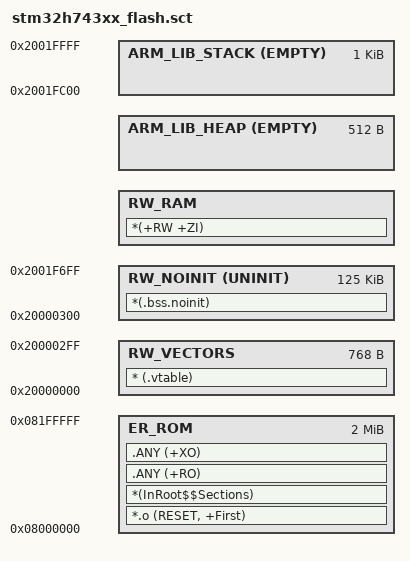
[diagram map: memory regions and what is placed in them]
#! armclang -E --target=arm-arm-none-eabi -mcpu=cortex-m7 -xc
; command above MUST be in first line (no comment above!)

/*
;-------- <<< Use Configuration Wizard in Context Menu >>> -------------------
*/

/*--------------------- Flash Configuration ----------------------------------
; <h> Flash Configuration
;   <o0> Flash Base Address <0x0-0xFFFFFFFF:8>
;   <o1> Flash Size (in Bytes) <0x0-0xFFFFFFFF:8>
; </h>
 *----------------------------------------------------------------------------*/
#define __ROM_BASE      0x08000000
#define __ROM_SIZE      0x00200000

/*--------------------- Embedded RAM DTCM Configuration -----------------------
; <h> RAM1 Configuration
;   <o0> RAM1 Base Address    <0x0-0xFFFFFFFF:8>
;   <o1> RAM1 Size (in Bytes) <0x0-0xFFFFFFFF:8>
;   <i> DTCM Speed: 400Mhz
;   <i> DTCM use for user data
; </h>
 *----------------------------------------------------------------------------*/
#define __RAM_BASE      0x20000000
#define __RAM_SIZE      0x00020000

/*--------------------- Embedded RAM AXI SRAM Configuration ------------------
; <h> RAM2 Configuration
;   <q> RAM2 Enable
;   <o1> RAM2 Base Address    <0x0-0xFFFFFFFF:8>
;   <o2> RAM2 Size (in Bytes) <0x0-0xFFFFFFFF:8>
;   <i> AXI SRAM Speed: 200Mhz
;   <i> AXI SRAM use for user data or LCD frame buffer
; </h>
 *----------------------------------------------------------------------------*/
#define __RAM2_ENABLE   0
#define __RAM2_BASE     0x24000000
#define __RAM2_SIZE     0x00080000

/*--------------------- Embedded RAM SRAM1/2/3 Configuration ------------------
; <h> RAM3 Configuration
;   <q> RAM3 Enable
;   <o1> RAM3 Base Address    <0x0-0xFFFFFFFF:8>
;   <o2> RAM3 Size (in Bytes) <0x0-0xFFFFFFFF:8>
;   <i> SRAM Speed: 200Mhz
;   <i> SRAM1(0x30000000) + SRAM2(0x30020000) + SRAM3(0x30040000)
;   <i> SRAM1 use for DMA buffer
;   <i> SRAM2 use for user data or DMA buffer
;   <i> SRAM3 use for USB or Ethernet peripheral data buffer
; </h>
 *----------------------------------------------------------------------------*/
#define __RAM3_ENABLE   0
#define __RAM3_BASE     0x30000000
#define __RAM3_SIZE     0x00048000

/*--------------------- Embedded RAM SRAM4 Configuration ----------------------
; <h> RAM4 Configuration
;   <q> RAM4 Enable
;   <o1> RAM4 Base Address    <0x0-0xFFFFFFFF:8>
;   <o2> RAM4 Size (in Bytes) <0x0-0xFFFFFFFF:8>
;   <i> SRAM Speed: 200Mhz
;   <i> SRAM4 use for user data or DMA buffer
; </h>
 *----------------------------------------------------------------------------*/
#define __RAM4_ENABLE   0
#define __RAM4_BASE     0x38000000
#define __RAM4_SIZE     0x00010000

/*--------------------- Event Recorder Configuration -------------------------
; <h> Event Recorder Configuration
;   <o> Event Recorder RAM Size (in Bytes) <0x0-0xFFFFFFFF:16>
;   <i> Memory requirement = 256 + (16 x Number_of_Records)
;   <i> (defined by EVENT_RECORD_COUNT in EventRecorderConf.h)
; </h>
 *----------------------------------------------------------------------------*/
#define __RAM_EVR_SIZE  0x00000000

/*--------------------- Vector Table Configuration ----------------------------
; <h> Vector Table Configuration
;   <o> Vector Table RAM Size (in Bytes) <0x0-0xFFFFFFFF:16>
; </h>
 *----------------------------------------------------------------------------*/
#define __VECTOR_SIZE   0x00000300

/*--------------------- Stack / Heap Configuration ---------------------------
; <h> Stack / Heap Configuration
;   <o0> Stack Size (in Bytes) <0x0-0xFFFFFFFF:8>
;   <o1> Heap Size (in Bytes) <0x0-0xFFFFFFFF:8>
; </h>
 *----------------------------------------------------------------------------*/
#define __STACK_SIZE    0x00000400
#define __HEAP_SIZE     0x00000200

/*
;------------- <<< end of configuration section >>> ---------------------------
*/


/*----------------------------------------------------------------------------
  User Stack & Heap boundary definition
 *----------------------------------------------------------------------------*/
#define __STACK_TOP    (__RAM_BASE + __RAM_SIZE)    /* starts at end of RAM */
#define __HEAP_BASE    (AlignExpr(+0, 8))           /* starts after RW_RAM section, 8 byte aligned */
#define __RAM_EVR_BASE (AlignExpr(+0, 4))           /* starts after previous section, 4 byte aligned */


/*----------------------------------------------------------------------------
  Scatter File Definitions definition
 *----------------------------------------------------------------------------*/
#define __RO_BASE           __ROM_BASE
#define __RO_SIZE           __ROM_SIZE

#define __RW_BASE           __RAM_BASE
#define __RW_SIZE           (__RAM_SIZE - __STACK_SIZE - __HEAP_SIZE - __VECTOR_SIZE - __RAM_EVR_SIZE)

LR_ROM __RO_BASE __RO_SIZE  {                       ; load region size_region
  ER_ROM __RO_BASE __RO_SIZE  {                     ; load address = execution address
   *.o (RESET, +First)
   *(InRoot$$Sections)
   .ANY (+RO)
   .ANY (+XO)
  }

#if __VECTOR_SIZE > 0
  RW_VECTORS __RW_BASE __VECTOR_SIZE {
    * (.vtable)
  }
  
  RW_NOINIT (__RW_BASE + __VECTOR_SIZE) UNINIT (__RW_SIZE - __VECTOR_SIZE) {
    *(.bss.noinit)
  }
#else
  RW_NOINIT __RW_BASE UNINIT __RW_SIZE {
    *(.bss.noinit)
  }
#endif

  RW_RAM AlignExpr(+0, 8) (__RW_SIZE - AlignExpr(ImageLength(RW_NOINIT), 8)) {
    *(+RW +ZI)
  }

#if __RAM2_ENABLE
  RW_RAM2 __RAM2_BASE __RAM2_SIZE {
    *(.RAM_D1)
  }
#endif

#if __RAM3_ENABLE
  RW_RAM3 __RAM3_BASE __RAM3_SIZE {
      *(.RAM_D2)
  }
#endif

#if __RAM4_ENABLE
  RW_RAM4 __RAM4_BASE __RAM4_SIZE {
      *(.RAM_D3)
  }
#endif

#if __RAM_EVR_SIZE > 0
  RW_EVR __RAM_EVR_BASE UNINIT __RAM_EVR_SIZE {     ; Event Recorder RAM region
    EventRecorder.o (+ZI)
  }
#endif

#if __HEAP_SIZE > 0
  ARM_LIB_HEAP  __HEAP_BASE EMPTY  __HEAP_SIZE  {   ; Reserve empty region for heap
  }
#endif

  ARM_LIB_STACK __STACK_TOP EMPTY -__STACK_SIZE {   ; Reserve empty region for stack
  }
}
